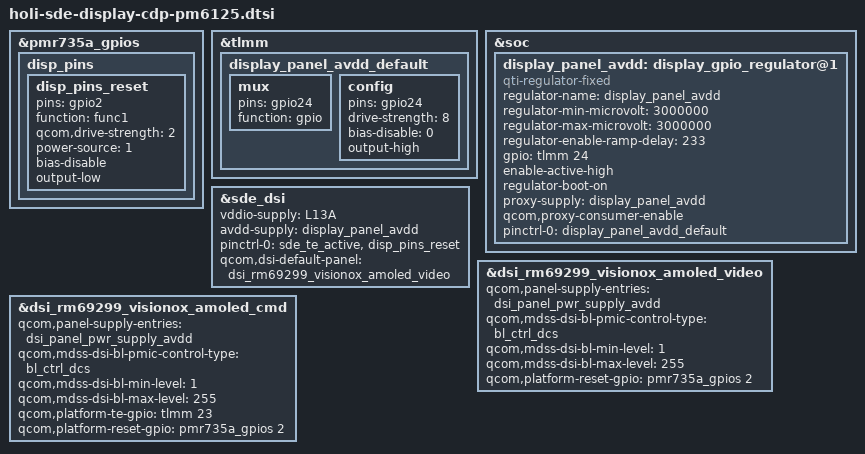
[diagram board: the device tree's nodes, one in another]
#include "holi-sde-display.dtsi"

&pmr735a_gpios {
	disp_pins {
		disp_pins_reset: disp_pins_reset {
			pins = "gpio2";
			function = "func1";
			qcom,drive-strength = <2>;
			power-source = <1>;
			bias-disable;
			output-low;
		};
	};
};

&tlmm {
	display_panel_avdd_default: display_panel_avdd_default {
		mux {
			pins = "gpio24";
			function = "gpio";
		};

		config {
			pins = "gpio24";
			drive-strength = <8>;
			bias-disable = <0>;
			output-high;
		};
	};
};

&soc {
	display_panel_avdd: display_gpio_regulator@1 {
		compatible = "qti-regulator-fixed";
		regulator-name = "display_panel_avdd";
		regulator-min-microvolt = <3000000>;
		regulator-max-microvolt = <3000000>;
		regulator-enable-ramp-delay = <233>;
		gpio = <&tlmm 24 0>;
		enable-active-high;
		regulator-boot-on;
		proxy-supply = <&display_panel_avdd>;
		qcom,proxy-consumer-enable;
		pinctrl-names = "default";
		pinctrl-0 = <&display_panel_avdd_default>;
	};
};

&sde_dsi {
	vddio-supply = <&L13A>;
	avdd-supply = <&display_panel_avdd>;

	/delete-property/ lab-supply;
	/delete-property/ ibb-supply;

	pinctrl-0 = <&sde_te_active &disp_pins_reset>;
	qcom,dsi-default-panel = <&dsi_rm69299_visionox_amoled_video>;
};

&dsi_rm69299_visionox_amoled_video {
	qcom,panel-supply-entries = <&dsi_panel_pwr_supply_avdd>;
	qcom,mdss-dsi-bl-pmic-control-type = "bl_ctrl_dcs";
	qcom,mdss-dsi-bl-min-level = <1>;
	qcom,mdss-dsi-bl-max-level = <255>;
	qcom,platform-reset-gpio = <&pmr735a_gpios 2 0>;
};

&dsi_rm69299_visionox_amoled_cmd {
	qcom,panel-supply-entries = <&dsi_panel_pwr_supply_avdd>;
	qcom,mdss-dsi-bl-pmic-control-type = "bl_ctrl_dcs";
	qcom,mdss-dsi-bl-min-level = <1>;
	qcom,mdss-dsi-bl-max-level = <255>;
	qcom,platform-te-gpio = <&tlmm 23 0>;
	qcom,platform-reset-gpio = <&pmr735a_gpios 2 0>;
};
